# STM32U595 register map
File version: 0.2
CPU: CM33 r0p1, little endian, MPU, FPU, 4 interrupt priority bits
Registers are 32-bit, read-write, reset 0x0 unless marked. A register's access mark holds for its fields unless they carry their own. Offsets are from the block's base; [hi:lo] are bit positions; {n}, {i} and the like mark numbered series.

## ADC1
Base 0x42028000
Same registers: ADC2 0x42028100, SEC_ADC1 0x52028000, SEC_ADC2 0x52028100
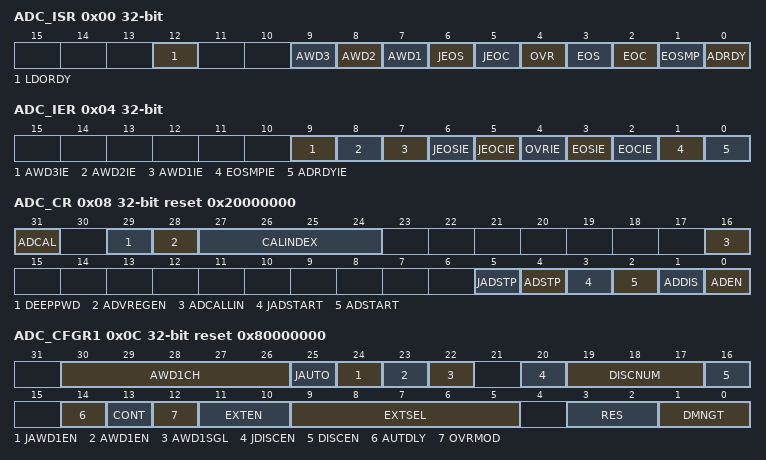
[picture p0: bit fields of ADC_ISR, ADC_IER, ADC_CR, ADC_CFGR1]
0x00 ADC_ISR access per field — ADC interrupt and status register
  [12] LDORDY ro, [9] AWD3 rw, [8] AWD2 rw, [7] AWD1 rw, [6] JEOS rw, [5] JEOC rw, [4] OVR rw, [3] EOS rw, [2] EOC rw, [1] EOSMP rw, [0] ADRDY rw
0x04 ADC_IER — ADC interrupt enable register
  [9] AWD3IE, [8] AWD2IE, [7] AWD1IE, [6] JEOSIE, [5] JEOCIE, [4] OVRIE, [3] EOSIE, [2] EOCIE, [1] EOSMPIE, [0] ADRDYIE
0x08 ADC_CR access per field reset 0x20000000 — ADC control register
  [31] ADCAL ro, [29] DEEPPWD rw, [28] ADVREGEN rw, [27:24] CALINDEX rw, [16] ADCALLIN rw, [5] JADSTP ro, [4] ADSTP ro, [3] JADSTART ro, [2] ADSTART ro, [1] ADDIS ro, [0] ADEN ro
0x0C ADC_CFGR1 reset 0x80000000 — ADC configuration register
  [30:26] AWD1CH, [25] JAUTO, [24] JAWD1EN, [23] AWD1EN, [22] AWD1SGL, [20] JDISCEN, [19:17] DISCNUM, [16] DISCEN, [14] AUTDLY, [13] CONT, [12] OVRMOD, [11:10] EXTEN, [9:5] EXTSEL, [3:2] RES, [1:0] DMNGT
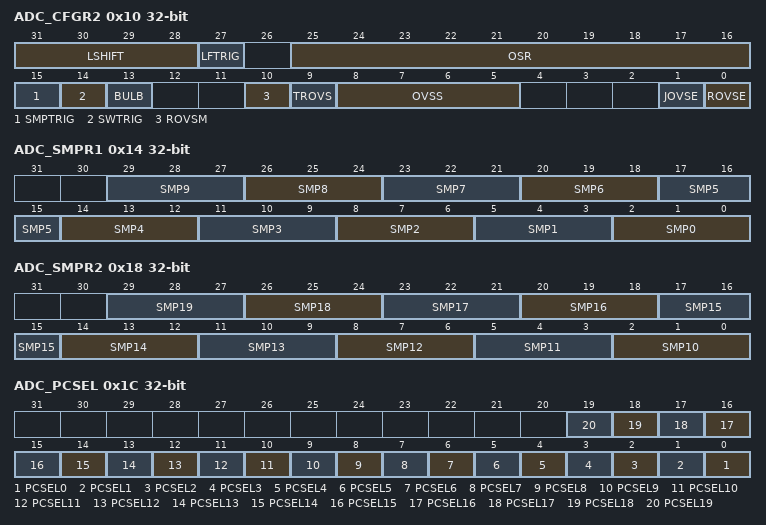
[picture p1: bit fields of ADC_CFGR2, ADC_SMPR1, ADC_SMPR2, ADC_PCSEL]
0x10 ADC_CFGR2 — ADC configuration register 2
  [31:28] LSHIFT, [27] LFTRIG, [25:16] OSR, [15] SMPTRIG, [14] SWTRIG, [13] BULB, [10] ROVSM, [9] TROVS, [8:5] OVSS, [1] JOVSE, [0] ROVSE
0x14 ADC_SMPR1 — ADC sample time register 1
  [3n+2:3n] SMP{n} (n=0..9)
0x18 ADC_SMPR2 — ADC sample time register 2
  [3n-28:3n-30] SMP{n} (n=10..19)
0x1C ADC_PCSEL — ADC channel preselection register
  [n] PCSEL{n} (n=0..19)
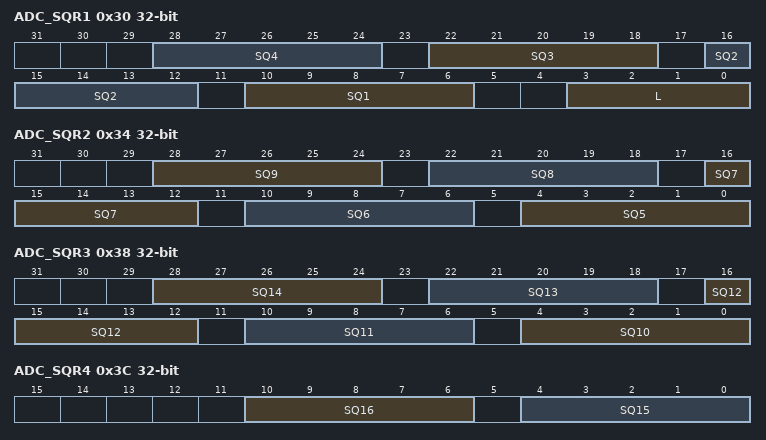
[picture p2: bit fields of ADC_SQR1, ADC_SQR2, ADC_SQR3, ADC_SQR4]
0x30 ADC_SQR1 — ADC regular sequence register 1
  [6n+4:6n] SQ{n} (n=1..4), [3:0] L
0x34 ADC_SQR2 — ADC regular sequence register 2
  [6n-26:6n-30] SQ{n} (n=5..9)
0x38 ADC_SQR3 — ADC regular sequence register 3
  [6n-56:6n-60] SQ{n} (n=10..14)
0x3C ADC_SQR4 — ADC regular sequence register 4
  [10:6] SQ16, [4:0] SQ15
0x40 ADC_DR ro — ADC regular Data Register
  [31:0] RDATA
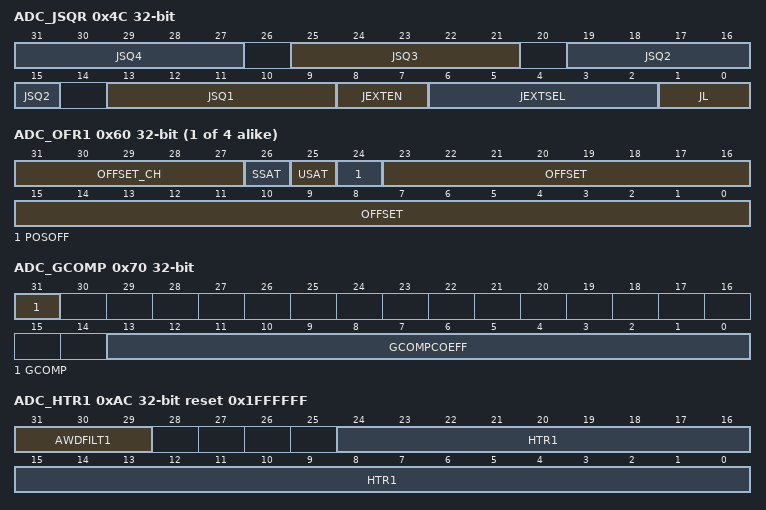
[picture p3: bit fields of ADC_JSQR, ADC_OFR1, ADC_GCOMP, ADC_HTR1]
0x4C ADC_JSQR — ADC injected sequence register
  [6n+7:6n+3] JSQ{n} (n=1..4), [8:7] JEXTEN, [6:2] JEXTSEL, [1:0] JL
{0x5C+4i} ADC_OFR{i} (i=1..4) — ADC offset register
  [31:27] OFFSET_CH, [26] SSAT, [25] USAT, [24] POSOFF, [23:0] OFFSET
0x70 ADC_GCOMP — ADC gain compensation register
  [31] GCOMP, [13:0] GCOMPCOEFF
{0x7C+4i} ADC_JDR{i} ro (i=1..4) — ADC injected data register
  [31:0] JDATA
0xA0 ADC_AWD2CR — ADC analog watchdog 2 configuration register
  [19:0] AWD2CH
0xA4 ADC_AWD3CR — ADC analog watchdog 3 configuration register
  [19:0] AWD3CH
0xA8 ADC_LTR1 — ADC watchdog threshold register 1
  [24:0] LTR1
0xAC ADC_HTR1 reset 0x1FFFFFF — ADC watchdog threshold register 1
  [31:29] AWDFILT1, [24:0] HTR1
0xB0 ADC_LTR2 — ADC watchdog lower threshold register 2
  [24:0] LTR2
0xB4 ADC_HTR2 reset 0x1FFFFFF — ADC watchdog higher threshold register 2
  [24:0] HTR2
0xB8 ADC_LTR3 — ADC watchdog lower threshold register 3
  [24:0] LTR3
0xBC ADC_HTR3 reset 0x1FFFFFF — ADC watchdog higher threshold register 3
  [24:0] HTR3
0xC0 ADC_DIFSEL — ADC differential mode selection register
  [19:0] DIFSEL
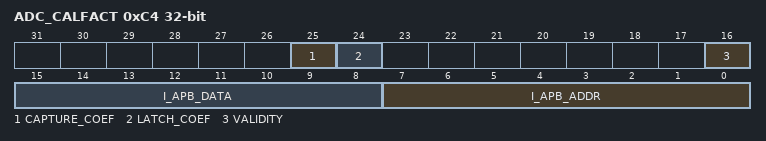
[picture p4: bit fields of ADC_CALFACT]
0xC4 ADC_CALFACT access per field — ADC user control register
  [25] CAPTURE_COEF rw, [24] LATCH_COEF rw, [16] VALIDITY ro, [15:8] I_APB_DATA ro, [7:0] I_APB_ADDR ro
0xC8 ADC_CALFACT2 — ADC calibration factor register
  [31:0] CALFACT

## ADC4
Base 0x46021000
Same registers: SEC_ADC4 0x56021000
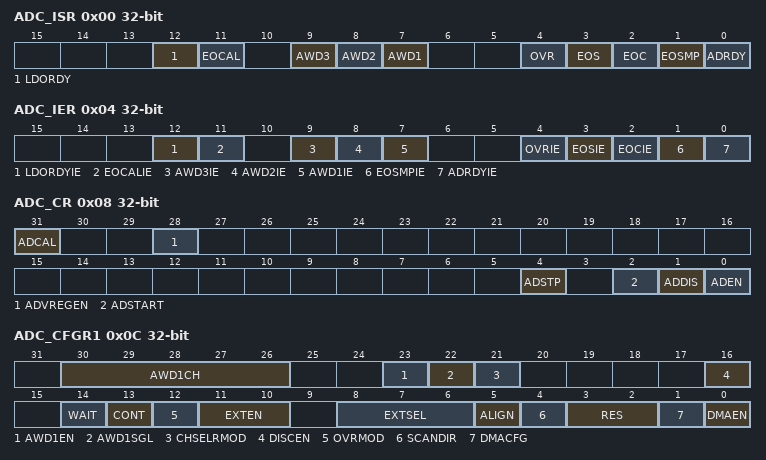
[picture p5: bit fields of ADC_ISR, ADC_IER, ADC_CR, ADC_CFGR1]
0x00 ADC_ISR — ADC interrupt and status register
  [12] LDORDY, [11] EOCAL, [9] AWD3, [8] AWD2, [7] AWD1, [4] OVR, [3] EOS, [2] EOC, [1] EOSMP, [0] ADRDY
0x04 ADC_IER — ADC interrupt enable register
  [12] LDORDYIE, [11] EOCALIE, [9] AWD3IE, [8] AWD2IE, [7] AWD1IE, [4] OVRIE, [3] EOSIE, [2] EOCIE, [1] EOSMPIE, [0] ADRDYIE
0x08 ADC_CR access per field — ADC control register
  [31] ADCAL ro, [28] ADVREGEN rw, [4] ADSTP ro, [2] ADSTART ro, [1] ADDIS ro, [0] ADEN ro
0x0C ADC_CFGR1 — ADC configuration register
  [30:26] AWD1CH, [23] AWD1EN, [22] AWD1SGL, [21] CHSELRMOD, [16] DISCEN, [14] WAIT, [13] CONT, [12] OVRMOD, [11:10] EXTEN, [8:6] EXTSEL, [5] ALIGN, [4] SCANDIR, [3:2] RES, [1] DMACFG, [0] DMAEN
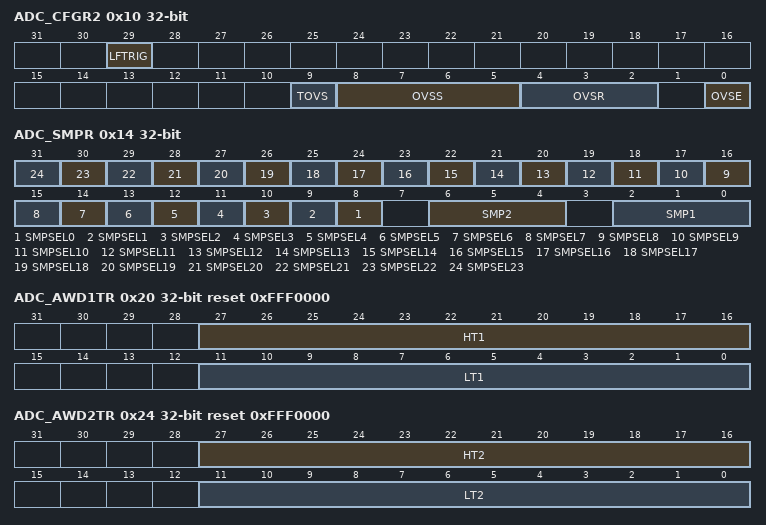
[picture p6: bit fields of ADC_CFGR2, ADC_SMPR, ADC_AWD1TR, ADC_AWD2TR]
0x10 ADC_CFGR2 — ADC configuration register 2
  [29] LFTRIG, [9] TOVS, [8:5] OVSS, [4:2] OVSR, [0] OVSE
0x14 ADC_SMPR — ADC sample time register
  [n+8] SMPSEL{n} (n=0..23), [6:4] SMP2, [2:0] SMP1
0x20 ADC_AWD1TR reset 0xFFF0000 — ADC watchdog threshold register
  [27:16] HT1, [11:0] LT1
0x24 ADC_AWD2TR reset 0xFFF0000 — ADC watchdog threshold register
  [27:16] HT2, [11:0] LT2
0x28 ADC_CHSELRMOD0 — ADC channel selection register [alternate]
  [23:0] CHSEL
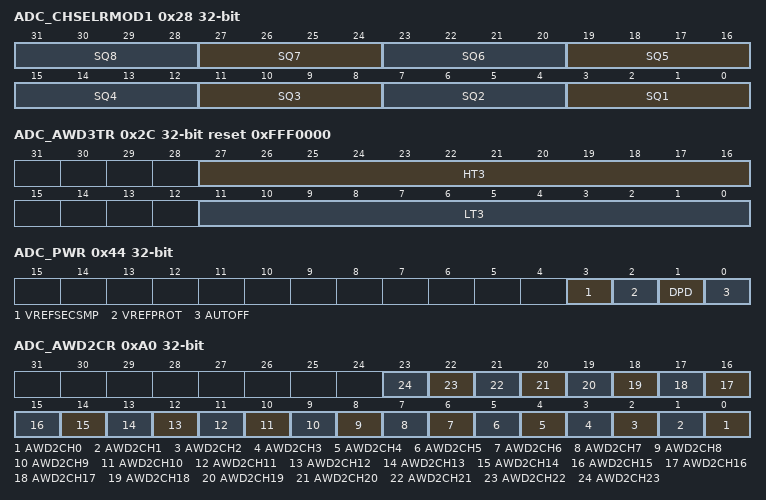
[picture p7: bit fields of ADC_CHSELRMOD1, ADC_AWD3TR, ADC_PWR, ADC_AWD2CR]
0x28 ADC_CHSELRMOD1 (alternate view of ADC_CHSELRMOD0) — ADC channel selection register [alternate]
  [4n-1:4n-4] SQ{n} (n=1..8)
0x2C ADC_AWD3TR reset 0xFFF0000 — ADC watchdog threshold register
  [27:16] HT3, [11:0] LT3
0x40 ADC_DR ro — ADC data register
  [15:0] DATA
0x44 ADC_PWR — ADC data register
  [3] VREFSECSMP, [2] VREFPROT, [1] DPD, [0] AUTOFF
0xA0 ADC_AWD2CR — ADC Analog Watchdog 2 Configuration register
  [n] AWD2CH{n} (n=0..23)
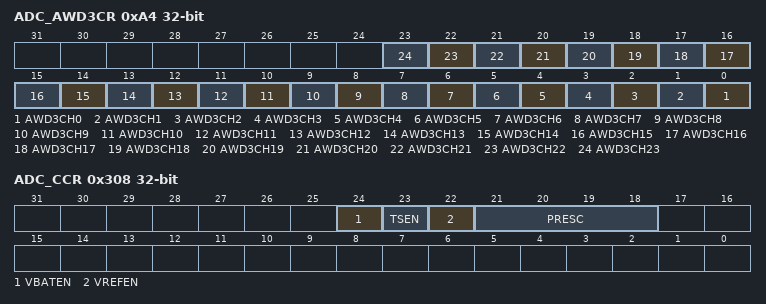
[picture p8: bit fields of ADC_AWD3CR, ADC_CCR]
0xA4 ADC_AWD3CR — ADC Analog Watchdog 3 Configuration register
  [n] AWD3CH{n} (n=0..23)
0xB4 ADC_CALFACT — ADC Calibration factor
  [6:0] CALFACT
0xD0 ADC_OR — ADC option register
  [0] CHN21SEL
0x308 ADC_CCR — ADC common configuration register
  [24] VBATEN, [23] TSEN, [22] VREFEN, [21:18] PRESC
